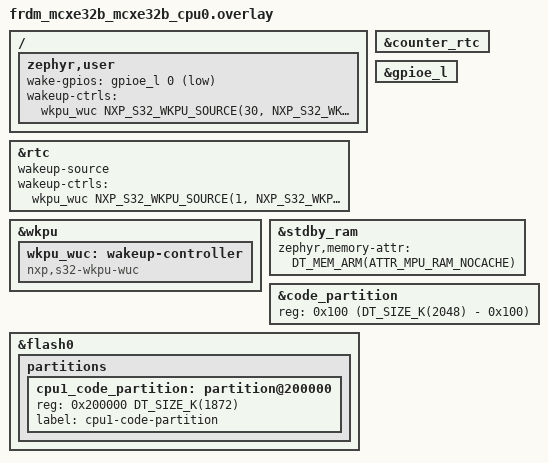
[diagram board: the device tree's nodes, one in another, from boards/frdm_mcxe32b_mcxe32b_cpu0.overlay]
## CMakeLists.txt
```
# Copyright 2026 NXP
#
# SPDX-License-Identifier: Apache-2.0

cmake_minimum_required(VERSION 3.28.0)
find_package(Zephyr REQUIRED HINTS $ENV{ZEPHYR_BASE})
project(frdm_mcxe31b_system_off)

target_sources(app PRIVATE src/main.c)
```

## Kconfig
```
# Copyright 2026 NXP
# SPDX-License-Identifier: Apache-2.0

mainmenu "MCXE system off demo"

choice APP_WAKEUP_SOURCE
	prompt "Standby wake-up source"
	default APP_WAKEUP_RTC

config APP_WAKEUP_RTC
	bool "RTC timeout"

config APP_WAKEUP_GPIO
	bool "External GPIO"
	depends on SOC_MCXE32B_CPU0
	select GPIO

config APP_WAKEUP_BOTH
	bool "RTC timeout or external GPIO"
	depends on SOC_MCXE32B_CPU0
	select GPIO

endchoice

config APP_USE_CPU1
	bool "Start and cooperatively stop CPU1 before standby"
	depends on SOC_MCXE32B_CPU0
	select ARM_MPU
	help
	  Requires the companion CPU1 image built by sysbuild. CPU0 requests
	  shutdown through non-cacheable standby SRAM and waits for CPU1's
	  acknowledgment and hardware WFI status before gating its clock.

config APP_TEST_CYCLES
	int "Number of standby cycles to execute"
	range 1 1000
	default 10
	help
	  Number of times the sample arms its wake-up sources and enters system off.
	  The completed cycle count is stored in standby-retained noinit memory
	  so it can be retrieved after each standby wake reset.

source "Kconfig.zephyr"
```

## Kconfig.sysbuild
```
# SPDX-FileCopyrightText: Copyright 2026 NXP
# SPDX-License-Identifier: Apache-2.0

source "share/sysbuild/Kconfig"

config APP_USE_CPU1
	bool "Build the companion CPU1 image"
	default y if $(BOARD) = "frdm_mcxe32b"
```

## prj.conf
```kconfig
#
# Copyright 2026 NXP
#
# SPDX-License-Identifier: Apache-2.0
#
CONFIG_POWEROFF=y

# Enable the RTC counter used as the wake-up alarm source
CONFIG_COUNTER=y
CONFIG_CACHE_MANAGEMENT=y
CONFIG_BUILD_OUTPUT_HEX=y
CONFIG_UART_INTERRUPT_DRIVEN=y
CONFIG_WUC=y
```

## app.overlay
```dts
/*
 * Copyright 2026 NXP
 *
 * SPDX-License-Identifier: Apache-2.0
 */

/*
 * Run the RTC on undivided SIRC. The prescaler/divider clock does not keep
 * running in standby, so a divided counter freezes and its alarm never fires;
 * the undivided counter is in the always-on domain and keeps advancing, so the
 * alarm can wake the SoC from standby.
 */
&rtc {
	prescaler = <1>;
};

&stdby_ram {
	compatible = "zephyr,memory-region", "mmio-sram";
	zephyr,memory-region = "STDBY_RAM";
	status = "okay";
};
```

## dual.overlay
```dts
/*
 * SPDX-FileCopyrightText: Copyright 2026 NXP
 *
 * SPDX-License-Identifier: Apache-2.0
 */

&sram {
	reg = <0x20408000 DT_SIZE_K(32)>;
};
```

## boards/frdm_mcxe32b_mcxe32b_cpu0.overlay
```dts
/*
 * SPDX-FileCopyrightText: Copyright 2026 NXP
 *
 * SPDX-License-Identifier: Apache-2.0
 */

#include <zephyr/dt-bindings/gpio/nxp-siul2-gpio.h>
#include <zephyr/dt-bindings/wuc/wuc_nxp_s32_wkpu.h>
#include "../app.overlay"

/ {
	zephyr,user {
		wake-gpios = <&gpioe_l 0 (GPIO_ACTIVE_LOW | GPIO_PULL_UP |
					  NXP_SIUL2_GPIO_INT_WKPU)>;
		wakeup-ctrls = <&wkpu_wuc
				NXP_S32_WKPU_SOURCE(30, NXP_S32_WKPU_EDGE_FALLING)>;
	};
};

&rtc {
	wakeup-source;
	wakeup-ctrls = <&wkpu_wuc NXP_S32_WKPU_SOURCE(1, NXP_S32_WKPU_EDGE_RISING)>;
	status = "okay";
};

&counter_rtc {
	status = "okay";
};

&gpioe_l {
	status = "okay";
};

&wkpu {
	status = "okay";

	wkpu_wuc: wakeup-controller {
		compatible = "nxp,s32-wkpu-wuc";
		#wakeup-ctrl-cells = <1>;
	};
};

&stdby_ram {
	zephyr,memory-attr = <DT_MEM_ARM(ATTR_MPU_RAM_NOCACHE)>;
};

&code_partition {
	reg = <0x100 (DT_SIZE_K(2048) - 0x100)>;
};

&flash0 {
	partitions {
		cpu1_code_partition: partition@200000 {
			reg = <0x200000 DT_SIZE_K(1872)>;
			label = "cpu1-code-partition";
		};
	};
};
```

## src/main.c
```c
/*
 * Copyright 2026 NXP
 *
 * SPDX-License-Identifier: Apache-2.0
 */

#include <stdio.h>

#include <zephyr/cache.h>
#include <zephyr/drivers/counter.h>
#include <zephyr/drivers/gpio.h>
#include <zephyr/drivers/uart.h>
#include <zephyr/drivers/wuc.h>
#include <zephyr/kernel.h>
#include <zephyr/linker/devicetree_regions.h>
#include <zephyr/pm/device.h>
#include <zephyr/sys/poweroff.h>
#include <zephyr/sys/clock.h>

#include <fsl_power.h>
#include <fsl_clock.h>

#include "standby.h"

#define WAKEUP_SECONDS 5

/*
 * Keep the boot reason visible briefly before entering standby again.
 */
#define RECOVERY_WINDOW_SECONDS 3

#define STANDBY_RAM_NODE DT_NODELABEL(stdby_ram)
#define STANDBY_RAM_SECTION LINKER_DT_NODE_REGION_NAME(STANDBY_RAM_NODE)

static struct standby_data retained Z_GENERIC_SECTION(STANDBY_RAM_SECTION);

#if defined(CONFIG_SOC_MCXE32B_CPU0)
static const struct wuc_dt_spec rtc_wuc = WUC_DT_SPEC_GET(DT_NODELABEL(rtc));
static const struct wuc_dt_spec gpio_wuc = WUC_DT_SPEC_GET(DT_PATH(zephyr_user));

static int prepare_wakeup_sources(bool standby_wake)
{
	int rtc_triggered;
	int gpio_triggered;
	int ret;

	if (!device_is_ready(rtc_wuc.dev) || !device_is_ready(gpio_wuc.dev)) {
		printf("FAIL: wake-up controller is not ready\n");
		return -ENODEV;
	}

	rtc_triggered = wuc_check_wakeup_source_triggered_dt(&rtc_wuc);
	gpio_triggered = wuc_check_wakeup_source_triggered_dt(&gpio_wuc);
	if (rtc_triggered < 0 || gpio_triggered < 0) {
		printf("FAIL: cannot query wake-up sources (RTC %d, GPIO %d)\n",
		       rtc_triggered, gpio_triggered);
		return rtc_triggered < 0 ? rtc_triggered : gpio_triggered;
	}
	if (standby_wake) {
		bool expected = (!IS_ENABLED(CONFIG_APP_WAKEUP_GPIO) && rtc_triggered == 1) ||
				(!IS_ENABLED(CONFIG_APP_WAKEUP_RTC) && gpio_triggered == 1);

		printf("Wake-up sources: RTC=%d GPIO=%d\n", rtc_triggered, gpio_triggered);
		if (!expected) {
			printf("FAIL: expected wake-up source was not recorded\n");
			return -EIO;
		}
	}

	ret = wuc_disable_wakeup_source_dt(&rtc_wuc);
	if (ret == 0) {
		ret = wuc_disable_wakeup_source_dt(&gpio_wuc);
	}
	if (ret == 0) {
		ret = wuc_clear_wakeup_source_triggered_dt(&rtc_wuc);
	}
	if (ret == 0) {
		ret = wuc_clear_wakeup_source_triggered_dt(&gpio_wuc);
	}
	if (ret < 0) {
		printf("FAIL: cannot reset wake-up routes (%d)\n", ret);
	}
	return ret;
}
#endif

static int set_standby_cycle_count(uint32_t count)
{
	retained.magic = STANDBY_MAGIC;
	retained.cycles = count;
	retained.check = ~count;
	if (IS_ENABLED(CONFIG_DCACHE)) {
		return sys_cache_data_flush_range(&retained, sizeof(retained));
	}
	return 0;
}

#if defined(CONFIG_APP_USE_CPU1)
static void update_cpu1_clock(bool enable)
{
	if (enable) {
		MC_ME->PRTN0_CORE1_PCONF |= MC_ME_PRTN0_CORE1_PCONF_CCE_MASK;
	} else {
		MC_ME->PRTN0_CORE1_PCONF &= ~MC_ME_PRTN0_CORE1_PCONF_CCE_MASK;
	}
	MC_ME->PRTN0_CORE1_PUPD = MC_ME_PRTN0_CORE1_PUPD_CCUPD_MASK;
	MC_ME->CTL_KEY = MC_ME_CTL_KEY_KEY(0x5AF0U);
	MC_ME->CTL_KEY = MC_ME_CTL_KEY_KEY(0xA50FU);
}

static int start_cpu1(void)
{
	if ((uintptr_t)&retained != DT_REG_ADDR(STANDBY_RAM_NODE)) {
		printf("FAIL: CPU1 mailbox is not at the start of standby SRAM\n");
		return -EINVAL;
	}
	if (MC_ME->PRTN0_CORE1_STAT & MC_ME_PRTN0_CORE1_STAT_CCS_MASK) {
		printf("FAIL: CPU1 was already enabled\n");
		return -EBUSY;
	}

	retained.request = 0U;
	retained.state = 0U;
	__DSB();
	MC_ME->PRTN0_CORE1_ADDR = DT_REG_ADDR(DT_NODELABEL(flash0)) +
				DT_REG_ADDR(DT_NODELABEL(cpu1_code_partition));
	update_cpu1_clock(true);

	if (!WAIT_FOR((MC_ME->PRTN0_CORE1_PUPD & MC_ME_PRTN0_CORE1_PUPD_CCUPD_MASK) == 0U &&
		      (MC_ME->PRTN0_CORE1_STAT & MC_ME_PRTN0_CORE1_STAT_CCS_MASK) != 0U &&
		      retained.state == CPU1_READY, 1000000, k_busy_wait(10))) {
		printf("FAIL: CPU1 did not start\n");
		return -ETIMEDOUT;
	}
	printf("CPU1 started\n");
	return 0;
}

static int stop_cpu1(void)
{
	retained.request = CPU1_STOP;
	__DSB();
	if (!WAIT_FOR(retained.state == CPU1_PARKED &&
		      (MC_ME->PRTN0_CORE1_STAT & MC_ME_PRTN0_CORE1_STAT_WFI_MASK) != 0U,
		      1000000, k_busy_wait(10))) {
		printf("FAIL: CPU1 did not acknowledge shutdown and enter WFI (state %u)\n",
		       retained.state);
		return -ETIMEDOUT;
	}

	update_cpu1_clock(false);
	if (!WAIT_FOR((MC_ME->PRTN0_CORE1_PUPD & MC_ME_PRTN0_CORE1_PUPD_CCUPD_MASK) == 0U &&
		      (MC_ME->PRTN0_CORE1_STAT & MC_ME_PRTN0_CORE1_STAT_CCS_MASK) == 0U,
		      100000, k_busy_wait(10))) {
		printf("FAIL: CPU1 clock did not stop\n");
		return -ETIMEDOUT;
	}
	printf("CPU1 parked and clock gated\n");
	return 0;
}
#endif

static void alarm_callback(const struct device *dev, uint8_t chan_id, uint32_t ticks,
			   void *user_data)
{
	/*
	 * Required by the counter API, but never actually invoked here: on
	 * MCXE31B the RTC alarm wakes the SoC out of standby as a functional
	 * reset, so execution restarts from main() rather than this callback.
	 */
	ARG_UNUSED(dev);
	ARG_UNUSED(chan_id);
	ARG_UNUSED(ticks);
	ARG_UNUSED(user_data);
}

int main(void)
{
	const struct device *const rtc = DEVICE_DT_GET(DT_NODELABEL(rtc));
	struct counter_alarm_cfg alarm_cfg = { 0 };
	bool standby_wake = POWER_ExitFromStandbyMode();
	int ret;

	if (standby_wake) {
		if (retained.magic != STANDBY_MAGIC || retained.check != ~retained.cycles ||
		    retained.cycles == 0U || retained.cycles > CONFIG_APP_TEST_CYCLES) {
			printf("FAIL: standby SRAM contents were not retained\n");
			return -EIO;
		}
		printf("Woke from standby\n");
		printf("Retained standby cycle count: %u/%u\n", retained.cycles,
		       CONFIG_APP_TEST_CYCLES);
	} else {
		ret = set_standby_cycle_count(0U);
		if (ret < 0) {
			printf("FAIL: cannot flush standby SRAM (%d)\n", ret);
			return ret;
		}
		printf("Cold boot\n");
	}

#if defined(CONFIG_SOC_MCXE32B_CPU0)
	ret = prepare_wakeup_sources(standby_wake);
	if (ret < 0) {
		return ret;
	}

	uint32_t rate = CLOCK_GetCoreClkFreq();

	printf("Run clock: %u Hz\n", rate);
	if (rate != DT_PROP(DT_NODELABEL(core0), clock_frequency)) {
		printf("FAIL: run clock was not restored\n");
		return -EIO;
	}
#endif

	if (retained.cycles >= CONFIG_APP_TEST_CYCLES) {
		ret = set_standby_cycle_count(0U);
		if (ret < 0) {
			printf("FAIL: cannot flush standby SRAM (%d)\n", ret);
			return ret;
		}
		printf("Completed %u standby cycles\n", CONFIG_APP_TEST_CYCLES);
		return 0;
	}

#if defined(CONFIG_APP_USE_CPU1)
	ret = start_cpu1();
	if (ret < 0) {
		return ret;
	}
#endif

	for (int i = RECOVERY_WINDOW_SECONDS; i > 0; i--) {
		printf("Powering off in %d s...\n", i);
		k_sleep(K_SECONDS(1));
	}

	if (!IS_ENABLED(CONFIG_APP_WAKEUP_GPIO)) {
		if (!device_is_ready(rtc)) {
			printf("FAIL: RTC device not ready\n");
			return -ENODEV;
		}

#if defined(CONFIG_SOC_MCXE32B_CPU0) && defined(CONFIG_PM_DEVICE)
		if (!pm_device_wakeup_enable(rtc, true)) {
			printf("FAIL: cannot enable RTC wake-up policy\n");
			return -ENOTSUP;
		}
#endif

		ret = counter_start(rtc);
		if (ret < 0) {
			printf("FAIL: could not start RTC counter (%d)\n", ret);
			return ret;
		}
	}

#if defined(CONFIG_APP_USE_CPU1)
	ret = stop_cpu1();
	if (ret < 0) {
		return ret;
	}
#endif

#if defined(CONFIG_APP_WAKEUP_GPIO) || defined(CONFIG_APP_WAKEUP_BOTH)
	const struct gpio_dt_spec wake = GPIO_DT_SPEC_GET(DT_PATH(zephyr_user), wake_gpios);

	if (!gpio_is_ready_dt(&wake)) {
		printf("FAIL: wake-up GPIO is not ready\n");
		return -ENODEV;
	}
	ret = gpio_pin_configure_dt(&wake, GPIO_INPUT);
	if (ret < 0) {
		printf("FAIL: could not configure wake-up GPIO (%d)\n", ret);
		return ret;
	}
	/* Allow the input buffer and pull-up to settle before checking the level. */
	k_sleep(K_MSEC(1));
	ret = gpio_pin_get_dt(&wake);
	if (ret != 0) {
		printf("FAIL: wake-up GPIO is already active or cannot be read (%d)\n", ret);
		return ret < 0 ? ret : -EBUSY;
	}
#endif

	/* No interrupt handler may consume a wake event between arming and WFI. */
	(void)irq_lock();

#if defined(CONFIG_APP_WAKEUP_GPIO) || defined(CONFIG_APP_WAKEUP_BOTH)
	ret = gpio_pin_interrupt_configure_dt(&wake, GPIO_INT_EDGE_TO_ACTIVE | GPIO_INT_WAKEUP);
	if (ret < 0) {
		printf("FAIL: could not arm GPIO wake-up (%d)\n", ret);
		k_panic();
	}
	printf("Wake-up GPIO PTE0 armed\n");
#endif

	if (!IS_ENABLED(CONFIG_APP_WAKEUP_GPIO)) {
		alarm_cfg.callback = alarm_callback;
		alarm_cfg.ticks = counter_us_to_ticks(rtc,
						     (uint64_t)WAKEUP_SECONDS * USEC_PER_SEC);
		ret = counter_set_channel_alarm(rtc, 0, &alarm_cfg);
		if (ret < 0) {
			printf("FAIL: could not set RTC alarm (%d)\n", ret);
			k_panic();
		}
		printf("Wake-up alarm set for %d seconds (cycle %u/%u)\n", WAKEUP_SECONDS,
		       retained.cycles + 1U, CONFIG_APP_TEST_CYCLES);
	}

	ret = set_standby_cycle_count(retained.cycles + 1U);
	if (ret < 0) {
		printf("FAIL: cannot flush standby SRAM (%d)\n", ret);
		k_panic();
	}
	printf("Powering off\n");

	const struct device *const console = DEVICE_DT_GET(DT_CHOSEN(zephyr_console));

	if (!WAIT_FOR(uart_irq_tx_complete(console) > 0, 10000, k_busy_wait(10))) {
		printf("FAIL: console transmission did not finish\n");
		k_panic();
	}

	sys_poweroff();

	return 0;
}
```

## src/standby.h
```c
/*
 * SPDX-FileCopyrightText: Copyright 2026 NXP
 *
 * SPDX-License-Identifier: Apache-2.0
 */

#ifndef MCXE_SYSTEM_OFF_STANDBY_H_
#define MCXE_SYSTEM_OFF_STANDBY_H_

#include <stdint.h>

#define STANDBY_MAGIC 0x53544259U
#define CPU1_READY 1U
#define CPU1_STOP 2U
#define CPU1_PARKED 3U
#define CPU1_ERROR 4U

struct standby_data {
	uint32_t magic;
	uint32_t cycles;
	uint32_t check;
	volatile uint32_t request;
	volatile uint32_t state;
};

#endif
```
